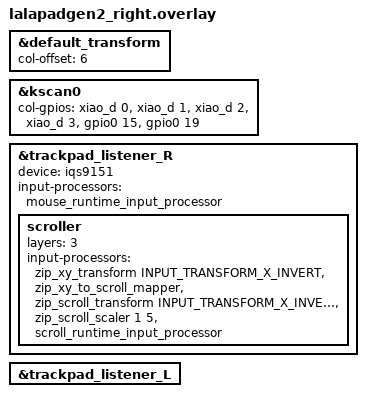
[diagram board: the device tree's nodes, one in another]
#include "lalapadgen2.dtsi"
#include <input/processors.dtsi>
#include <input/processors/runtime-input-processor.dtsi>

&default_transform {
    col-offset = <6>;
};

&kscan0 {
    col-gpios
        = <&xiao_d 0 GPIO_ACTIVE_HIGH>
        , <&xiao_d 1 GPIO_ACTIVE_HIGH>
        , <&xiao_d 2 GPIO_ACTIVE_HIGH>
        , <&xiao_d 3 GPIO_ACTIVE_HIGH>
        , <&gpio0 15 GPIO_ACTIVE_HIGH>
        , <&gpio0 19 GPIO_ACTIVE_HIGH>
        ;
};

&trackpad_listener_R {
    status = "okay";
    device = <&iqs9151>;
    input-processors = <&mouse_runtime_input_processor>;

scroller {
        layers = <3>;
        input-processors =
            <&zip_xy_transform INPUT_TRANSFORM_X_INVERT
             &zip_xy_to_scroll_mapper
             &zip_scroll_transform INPUT_TRANSFORM_X_INVERT
             &zip_scroll_scaler 1 5
             &scroll_runtime_input_processor>;
    };
};
&trackpad_listener_L {
    status = "okay";
};
